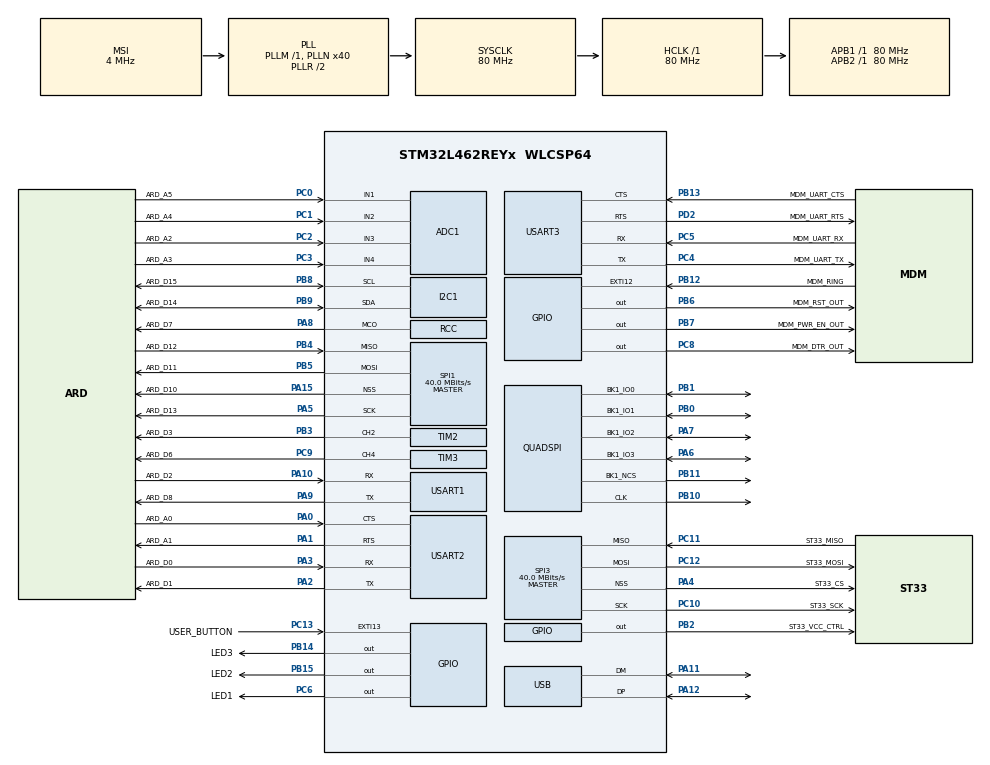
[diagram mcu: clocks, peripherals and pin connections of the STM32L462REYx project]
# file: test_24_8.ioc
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ADC1.Channel-4\#ChannelRegularConversion=ADC_CHANNEL_1
ADC1.NbrOfConversionFlag=1
ADC1.OffsetNumber-4\#ChannelRegularConversion=ADC_OFFSET_NONE
ADC1.Rank-4\#ChannelRegularConversion=1
ADC1.SamplingTime-4\#ChannelRegularConversion=ADC_SAMPLETIME_2CYCLES_5
ADC1.SingleDiff-4\#ChannelRegularConversion=ADC_DIFFERENTIAL_ENDED
ADC1.master=1
FREERTOS.Tasks01=defaultTask,0,128,StartDefaultTask,Default,NULL
FREERTOS.configUSE_NEWLIB_REENTRANT=1
Mcu.Family=STM32L4
Mcu.Name=STM32L462REYx
Mcu.Package=WLCSP64
NVIC.EXTI15_10_IRQn=true\:5\:0\:false\:false\:true\:true\:true\:true\:true
NVIC.PriorityGroup=NVIC_PRIORITYGROUP_4
NVIC.TIM1_UP_TIM16_IRQn=true\:0\:0\:false\:false\:true\:false\:false\:true\:true
NVIC.TimeBase=TIM1_UP_TIM16_IRQn
NVIC.TimeBaseIP=TIM1
NVIC.USART1_IRQn=true\:5\:0\:false\:false\:true\:true\:true\:true\:true
NVIC.USART2_IRQn=true\:5\:0\:false\:false\:true\:true\:true\:true\:true
NVIC.USART3_IRQn=true\:5\:0\:false\:false\:true\:true\:true\:true\:true
PA0.GPIO_Label=ARD_A0
PA0.Mode=CTS_RTS
PA0.Signal=USART2_CTS
PA1.GPIO_Label=ARD_A1
PA1.Mode=CTS_RTS
PA1.Signal=USART2_RTS
PA10.GPIO_Label=ARD_D2
PA10.Mode=Asynchronous
PA10.Signal=USART1_RX
PA11.Mode=Device
PA11.Signal=USB_DM
PA12.Mode=Device
PA12.Signal=USB_DP
PA13\ (JTMS/SWDIO).Mode=Serial_Wire
PA13\ (JTMS/SWDIO).Signal=SYS_JTMS-SWDIO
PA14\ (JTCK/SWCLK).Mode=Serial_Wire
PA14\ (JTCK/SWCLK).Signal=SYS_JTCK-SWCLK
PA15\ (JTDI).GPIO_Label=ARD_D10
PA15\ (JTDI).Mode=NSS_Signal_Hard_Output
PA15\ (JTDI).Signal=SPI1_NSS
PA2.GPIO_Label=ARD_D1
PA2.Mode=Asynchronous
PA2.Signal=USART2_TX
PA3.GPIO_Label=ARD_D0
PA3.Mode=Asynchronous
PA3.Signal=USART2_RX
PA4.GPIO_Label=ST33_CS
PA4.Mode=NSS_Signal_Hard_Output
PA4.Signal=SPI3_NSS
PA5.GPIO_Label=ARD_D13
PA5.Mode=Full_Duplex_Master
PA5.Signal=SPI1_SCK
PA6.Mode=Single Bank 1
PA6.Signal=QUADSPI_BK1_IO3
PA7.Mode=Single Bank 1
PA7.Signal=QUADSPI_BK1_IO2
PA8.GPIO_Label=ARD_D7
PA8.Mode=Clock-out
PA8.Signal=RCC_MCO
PA9.GPIO_Label=ARD_D8
PA9.Mode=Asynchronous
PA9.Signal=USART1_TX
PB0.Mode=Single Bank 1
PB0.Signal=QUADSPI_BK1_IO1
PB1.Mode=Single Bank 1
PB1.Signal=QUADSPI_BK1_IO0
PB10.Mode=Single Bank 1
PB10.Signal=QUADSPI_CLK
PB11.Mode=Single Bank 1
PB11.Signal=QUADSPI_BK1_NCS
PB12.GPIO_Label=MDM_RING
PB12.Signal=GPXTI12
PB13.GPIO_Label=MDM_UART_CTS
PB13.Mode=CTS_RTS
PB13.Signal=USART3_CTS
PB14.GPIO_Label=LED3
PB14.Signal=GPIO_Output
PB15.GPIO_Label=LED2
PB15.Signal=GPIO_Output
PB2.GPIO_Label=ST33_VCC_CTRL
PB2.Signal=GPIO_Output
PB3\ (JTDO/TRACESWO).GPIO_Label=ARD_D3
PB3\ (JTDO/TRACESWO).Signal=S_TIM2_CH2
PB4\ (NJTRST).GPIO_Label=ARD_D12
PB4\ (NJTRST).Mode=Full_Duplex_Master
PB4\ (NJTRST).Signal=SPI1_MISO
PB5.GPIO_Label=ARD_D11
PB5.Mode=Full_Duplex_Master
PB5.Signal=SPI1_MOSI
PB6.GPIO_Label=MDM_RST_OUT
PB6.Signal=GPIO_Output
PB7.GPIO_Label=MDM_PWR_EN_OUT
PB7.Signal=GPIO_Output
PB8.GPIO_Label=ARD_D15
PB8.GPIO_Pu=GPIO_PULLUP
PB8.Mode=I2C
PB8.Signal=I2C1_SCL
PB9.GPIO_Label=ARD_D14
PB9.GPIO_Pu=GPIO_PULLUP
PB9.Mode=I2C
PB9.Signal=I2C1_SDA
PC0.GPIO_Label=ARD_A5
PC0.Signal=ADCx_IN1
PC1.GPIO_Label=ARD_A4
PC1.Signal=ADCx_IN2
PC10.GPIO_Label=ST33_SCK
PC10.Mode=Full_Duplex_Master
PC10.Signal=SPI3_SCK
PC11.GPIO_Label=ST33_MISO
PC11.Mode=Full_Duplex_Master
PC11.Signal=SPI3_MISO
PC12.GPIO_Label=ST33_MOSI
PC12.Mode=Full_Duplex_Master
PC12.Signal=SPI3_MOSI
PC13.GPIO_Label=USER_BUTTON
PC13.GPIO_ModeDefaultEXTI=GPIO_MODE_IT_FALLING
PC13.Signal=GPXTI13
PC14-OSC32_IN\ (PC14).Mode=LSE-External-Oscillator
PC14-OSC32_IN\ (PC14).Signal=RCC_OSC32_IN
PC15-OSC32_OUT\ (PC15).Mode=LSE-External-Oscillator
PC15-OSC32_OUT\ (PC15).Signal=RCC_OSC32_OUT
PC2.GPIO_Label=ARD_A2
PC2.Signal=ADCx_IN3
PC3.GPIO_Label=ARD_A3
PC3.Signal=ADCx_IN4
PC4.GPIO_Label=MDM_UART_TX
PC4.Mode=Asynchronous
PC4.Signal=USART3_TX
PC5.GPIO_Label=MDM_UART_RX
PC5.Mode=Asynchronous
PC5.Signal=USART3_RX
PC6.GPIO_Label=LED1
PC6.Signal=GPIO_Output
PC8.GPIO_Label=MDM_DTR_OUT
PC8.Signal=GPIO_Output
PC9.GPIO_Label=ARD_D6
PC9.Signal=S_TIM3_CH4
PD2.GPIO_Label=MDM_UART_RTS
PD2.Mode=CTS_RTS
PD2.Signal=USART3_RTS
PH0-OSC_IN\ (PH0).Mode=HSE-External-Oscillator
PH0-OSC_IN\ (PH0).Signal=RCC_OSC_IN
PH1-OSC_OUT\ (PH1).Mode=HSE-External-Oscillator
PH1-OSC_OUT\ (PH1).Signal=RCC_OSC_OUT
ProjectManager.HeapSize=0x200
ProjectManager.StackSize=0x400
ProjectManager.TargetToolchain=STM32CubeIDE
RCC.ADCFreq_Value=48000000
RCC.AHBFreq_Value=80000000
RCC.APB1Freq_Value=80000000
RCC.APB1TimFreq_Value=80000000
RCC.APB2Freq_Value=80000000
RCC.APB2TimFreq_Value=80000000
RCC.CortexFreq_Value=80000000
RCC.HCLKFreq_Value=80000000
RCC.HSE_VALUE=8000000
RCC.HSI48_VALUE=48000000
RCC.HSI_VALUE=16000000
RCC.MSI_VALUE=4000000
RCC.PLLN=40
RCC.PLLSAI1N=24
RCC.RTCClockSelection=RCC_RTCCLKSOURCE_LSE
RCC.SYSCLKFreq_VALUE=80000000
RCC.SYSCLKSource=RCC_SYSCLKSOURCE_PLLCLK
RCC.USBFreq_Value=48000000
RCC.VCOOutputFreq_Value=160000000
SH.ADCx_IN1.0=ADC1_IN1,IN1-Differential
SH.ADCx_IN2.0=ADC1_IN2,IN1-Differential
SH.ADCx_IN3.0=ADC1_IN3,IN3-Differential
SH.ADCx_IN4.0=ADC1_IN4,IN3-Differential
SH.S_TIM2_CH2.0=TIM2_CH2,PWM Generation2 CH2
SH.S_TIM3_CH4.0=TIM3_CH4,PWM Generation4 CH4
SPI1.CalculateBaudRate=40.0 MBits/s
SPI1.Direction=SPI_DIRECTION_2LINES
SPI1.Mode=SPI_MODE_MASTER
SPI1.VirtualNSS=VM_NSSHARD
SPI1.VirtualType=VM_MASTER
SPI3.CalculateBaudRate=40.0 MBits/s
SPI3.Direction=SPI_DIRECTION_2LINES
SPI3.Mode=SPI_MODE_MASTER
SPI3.VirtualNSS=VM_NSSHARD
SPI3.VirtualType=VM_MASTER
TIM2.Channel-PWM\ Generation2\ CH2=TIM_CHANNEL_2
TIM3.Channel-PWM\ Generation4\ CH4=TIM_CHANNEL_4
USART1.VirtualMode-Asynchronous=VM_ASYNC
USART2.VirtualMode-Asynchronous=VM_ASYNC
USART3.VirtualMode-Asynchronous=VM_ASYNC
VP_FREERTOS_VS_CMSIS_V1.Mode=CMSIS_V1
VP_RNG_VS_RNG.Mode=RNG_Activate
VP_RTC_VS_RTC_Activate.Mode=RTC_Enabled
VP_SYS_VS_tim1.Mode=TIM1
board=B-L462E-CELL1

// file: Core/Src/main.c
/* USER CODE BEGIN Header */
/**
  ******************************************************************************
  * @file           : main.c
  * @brief          : Main program body
  ******************************************************************************
  * @attention
  *
  * Copyright (c) 2025 STMicroelectronics.
  * All rights reserved.
  *
  * This software is licensed under terms that can be found in the LICENSE file
  * in the root directory of this software component.
  * If no LICENSE file comes with this software, it is provided AS-IS.
  *
  ******************************************************************************
  */
/* USER CODE END Header */
#include "main.h"
#include "cmsis_os.h"
#include <string.h>
#include <stdio.h>
#include "lsm303agr.h"

ADC_HandleTypeDef hadc1;

I2C_HandleTypeDef hi2c1;

QSPI_HandleTypeDef hqspi;

RNG_HandleTypeDef hrng;

RTC_HandleTypeDef hrtc;

SPI_HandleTypeDef hspi1;
SPI_HandleTypeDef hspi3;

TIM_HandleTypeDef htim2;
TIM_HandleTypeDef htim3;

UART_HandleTypeDef huart1;
UART_HandleTypeDef huart2;
UART_HandleTypeDef huart3;

PCD_HandleTypeDef hpcd_USB_FS;

osThreadId defaultTaskHandle;

void SystemClock_Config(void);
void PeriphCommonClock_Config(void);
static void MX_GPIO_Init(void);
static void MX_ADC1_Init(void);
static void MX_I2C1_Init(void);
static void MX_QUADSPI_Init(void);
static void MX_RNG_Init(void);
static void MX_RTC_Init(void);
static void MX_SPI1_Init(void);
static void MX_SPI3_Init(void);
static void MX_TIM2_Init(void);
static void MX_TIM3_Init(void);
static void MX_USART1_UART_Init(void);
static void MX_USART2_UART_Init(void);
static void MX_USART3_UART_Init(void);
static void MX_USB_PCD_Init(void);
void StartDefaultTask(void const * argument);

static int16_t accel_data[3];
static char uart_tx_buffer[100];
static char msg[] = "Hello World!\r\n";

int main(void)
{

  /* MCU Configuration--------------------------------------------------------*/

  /* Reset of all peripherals, Initializes the Flash interface and the Systick. */
  HAL_Init();

  /* Configure the system clock */
  SystemClock_Config();

  /* Configure the peripherals common clocks */
  PeriphCommonClock_Config();

  /* Initialize all configured peripherals */
  MX_GPIO_Init();
  MX_ADC1_Init();
  MX_I2C1_Init();
  MX_QUADSPI_Init();
  MX_RNG_Init();
  MX_RTC_Init();
  MX_SPI1_Init();
  MX_SPI3_Init();
  MX_TIM2_Init();
  MX_TIM3_Init();
  MX_USART1_UART_Init();
  MX_USART2_UART_Init();
  MX_USART3_UART_Init();
  MX_USB_PCD_Init();
  /* USER CODE BEGIN 2 */
  uint16_t accel_config = LSM303AGR_ODR_100_HZ | LSM303AGR_AXES_ENABLE;
  LSM303AGR_AccInit(accel_config);
  /* USER CODE END 2 */

  /* Create the thread(s) */
  /* definition and creation of defaultTask */
  osThreadDef(defaultTask, StartDefaultTask, osPriorityNormal, 0, 128);
  defaultTaskHandle = osThreadCreate(osThread(defaultTask), NULL);

  /* Start scheduler */
  osKernelStart();

  /* We should never get here as control is now taken by the scheduler */

  /* Infinite loop */
  while (1)
  {

  }
}

void SystemClock_Config(void)
{
  RCC_OscInitTypeDef RCC_OscInitStruct = {0};
  RCC_ClkInitTypeDef RCC_ClkInitStruct = {0};

  /** Configure the main internal regulator output voltage
  */
  if (HAL_PWREx_ControlVoltageScaling(PWR_REGULATOR_VOLTAGE_SCALE1) != HAL_OK)
  {
    Error_Handler();
  }

  /** Configure LSE Drive Capability
  */
  HAL_PWR_EnableBkUpAccess();
  __HAL_RCC_LSEDRIVE_CONFIG(RCC_LSEDRIVE_LOW);

  /** Initializes the RCC Oscillators according to the specified parameters
  * in the RCC_OscInitTypeDef structure.
  */
  RCC_OscInitStruct.OscillatorType = RCC_OSCILLATORTYPE_LSE|RCC_OSCILLATORTYPE_MSI;
  RCC_OscInitStruct.LSEState = RCC_LSE_ON;
  RCC_OscInitStruct.MSIState = RCC_MSI_ON;
  RCC_OscInitStruct.MSICalibrationValue = 0;
  RCC_OscInitStruct.MSIClockRange = RCC_MSIRANGE_6;
  RCC_OscInitStruct.PLL.PLLState = RCC_PLL_ON;
  RCC_OscInitStruct.PLL.PLLSource = RCC_PLLSOURCE_MSI;
  RCC_OscInitStruct.PLL.PLLM = 1;
  RCC_OscInitStruct.PLL.PLLN = 40;
  RCC_OscInitStruct.PLL.PLLP = RCC_PLLP_DIV7;
  RCC_OscInitStruct.PLL.PLLQ = RCC_PLLQ_DIV2;
  RCC_OscInitStruct.PLL.PLLR = RCC_PLLR_DIV2;
  if (HAL_RCC_OscConfig(&RCC_OscInitStruct) != HAL_OK)
  {
    Error_Handler();
  }

  /** Initializes the CPU, AHB and APB buses clocks
  */
  RCC_ClkInitStruct.ClockType = RCC_CLOCKTYPE_HCLK|RCC_CLOCKTYPE_SYSCLK
                              |RCC_CLOCKTYPE_PCLK1|RCC_CLOCKTYPE_PCLK2;
  RCC_ClkInitStruct.SYSCLKSource = RCC_SYSCLKSOURCE_PLLCLK;
  RCC_ClkInitStruct.AHBCLKDivider = RCC_SYSCLK_DIV1;
  RCC_ClkInitStruct.APB1CLKDivider = RCC_HCLK_DIV1;
  RCC_ClkInitStruct.APB2CLKDivider = RCC_HCLK_DIV1;

  if (HAL_RCC_ClockConfig(&RCC_ClkInitStruct, FLASH_LATENCY_4) != HAL_OK)
  {
    Error_Handler();
  }
  HAL_RCC_MCOConfig(RCC_MCO1, RCC_MCO1SOURCE_SYSCLK, RCC_MCODIV_1);

  /** Enable MSI Auto calibration
  */
  HAL_RCCEx_EnableMSIPLLMode();
}

void PeriphCommonClock_Config(void)
{
  RCC_PeriphCLKInitTypeDef PeriphClkInit = {0};

  /** Initializes the peripherals clock
  */
  PeriphClkInit.PeriphClockSelection = RCC_PERIPHCLK_USB|RCC_PERIPHCLK_RNG
                              |RCC_PERIPHCLK_ADC;
  PeriphClkInit.AdcClockSelection = RCC_ADCCLKSOURCE_PLLSAI1;
  PeriphClkInit.UsbClockSelection = RCC_USBCLKSOURCE_PLLSAI1;
  PeriphClkInit.RngClockSelection = RCC_RNGCLKSOURCE_PLLSAI1;
  PeriphClkInit.PLLSAI1.PLLSAI1Source = RCC_PLLSOURCE_MSI;
  PeriphClkInit.PLLSAI1.PLLSAI1M = 1;
  PeriphClkInit.PLLSAI1.PLLSAI1N = 24;
  PeriphClkInit.PLLSAI1.PLLSAI1P = RCC_PLLP_DIV7;
  PeriphClkInit.PLLSAI1.PLLSAI1Q = RCC_PLLQ_DIV2;
  PeriphClkInit.PLLSAI1.PLLSAI1R = RCC_PLLR_DIV2;
  PeriphClkInit.PLLSAI1.PLLSAI1ClockOut = RCC_PLLSAI1_48M2CLK|RCC_PLLSAI1_ADC1CLK;
  if (HAL_RCCEx_PeriphCLKConfig(&PeriphClkInit) != HAL_OK)
  {
    Error_Handler();
  }
}

static void MX_ADC1_Init(void)
{

  ADC_ChannelConfTypeDef sConfig = {0};

  /** Common config
  */
  hadc1.Instance = ADC1;
  hadc1.Init.ClockPrescaler = ADC_CLOCK_ASYNC_DIV1;
  hadc1.Init.Resolution = ADC_RESOLUTION_12B;
  hadc1.Init.DataAlign = ADC_DATAALIGN_RIGHT;
  hadc1.Init.ScanConvMode = ADC_SCAN_DISABLE;
  hadc1.Init.EOCSelection = ADC_EOC_SINGLE_CONV;
  hadc1.Init.LowPowerAutoWait = DISABLE;
  hadc1.Init.ContinuousConvMode = DISABLE;
  hadc1.Init.NbrOfConversion = 1;
  hadc1.Init.DiscontinuousConvMode = DISABLE;
  hadc1.Init.ExternalTrigConv = ADC_SOFTWARE_START;
  hadc1.Init.ExternalTrigConvEdge = ADC_EXTERNALTRIGCONVEDGE_NONE;
  hadc1.Init.DMAContinuousRequests = DISABLE;
  hadc1.Init.Overrun = ADC_OVR_DATA_PRESERVED;
  hadc1.Init.OversamplingMode = DISABLE;
  if (HAL_ADC_Init(&hadc1) != HAL_OK)
  {
    Error_Handler();
  }

  /** Configure Regular Channel
  */
  sConfig.Channel = ADC_CHANNEL_1;
  sConfig.Rank = ADC_REGULAR_RANK_1;
  sConfig.SamplingTime = ADC_SAMPLETIME_2CYCLES_5;
  sConfig.SingleDiff = ADC_DIFFERENTIAL_ENDED;
  sConfig.OffsetNumber = ADC_OFFSET_NONE;
  sConfig.Offset = 0;
  if (HAL_ADC_ConfigChannel(&hadc1, &sConfig) != HAL_OK)
  {
    Error_Handler();
  }

}

static void MX_I2C1_Init(void)
{

  hi2c1.Instance = I2C1;
  hi2c1.Init.Timing = 0x00000E14;
  hi2c1.Init.OwnAddress1 = 0;
  hi2c1.Init.AddressingMode = I2C_ADDRESSINGMODE_7BIT;
  hi2c1.Init.DualAddressMode = I2C_DUALADDRESS_DISABLE;
  hi2c1.Init.OwnAddress2 = 0;
  hi2c1.Init.OwnAddress2Masks = I2C_OA2_NOMASK;
  hi2c1.Init.GeneralCallMode = I2C_GENERALCALL_DISABLE;
  hi2c1.Init.NoStretchMode = I2C_NOSTRETCH_DISABLE;
  if (HAL_I2C_Init(&hi2c1) != HAL_OK)
  {
    Error_Handler();
  }

  /** Configure Analogue filter
  */
  if (HAL_I2CEx_ConfigAnalogFilter(&hi2c1, I2C_ANALOGFILTER_ENABLE) != HAL_OK)
  {
    Error_Handler();
  }

  /** Configure Digital filter
  */
  if (HAL_I2CEx_ConfigDigitalFilter(&hi2c1, 0) != HAL_OK)
  {
    Error_Handler();
  }

}

static void MX_QUADSPI_Init(void)
{

  /* QUADSPI parameter configuration*/
  hqspi.Instance = QUADSPI;
  hqspi.Init.ClockPrescaler = 255;
  hqspi.Init.FifoThreshold = 1;
  hqspi.Init.SampleShifting = QSPI_SAMPLE_SHIFTING_NONE;
  hqspi.Init.FlashSize = 1;
  hqspi.Init.ChipSelectHighTime = QSPI_CS_HIGH_TIME_1_CYCLE;
  hqspi.Init.ClockMode = QSPI_CLOCK_MODE_0;
  hqspi.Init.FlashID = QSPI_FLASH_ID_1;
  hqspi.Init.DualFlash = QSPI_DUALFLASH_DISABLE;
  if (HAL_QSPI_Init(&hqspi) != HAL_OK)
  {
    Error_Handler();
  }

}

static void MX_RNG_Init(void)
{

  hrng.Instance = RNG;
  if (HAL_RNG_Init(&hrng) != HAL_OK)
  {
    Error_Handler();
  }

}

static void MX_RTC_Init(void)
{

  /** Initialize RTC Only
  */
  hrtc.Instance = RTC;
  hrtc.Init.HourFormat = RTC_HOURFORMAT_24;
  hrtc.Init.AsynchPrediv = 127;
  hrtc.Init.SynchPrediv = 255;
  hrtc.Init.OutPut = RTC_OUTPUT_DISABLE;
  hrtc.Init.OutPutRemap = RTC_OUTPUT_REMAP_NONE;
  hrtc.Init.OutPutPolarity = RTC_OUTPUT_POLARITY_HIGH;
  hrtc.Init.OutPutType = RTC_OUTPUT_TYPE_OPENDRAIN;
  if (HAL_RTC_Init(&hrtc) != HAL_OK)
  {
    Error_Handler();
  }

}

static void MX_SPI1_Init(void)
{

  /* SPI1 parameter configuration*/
  hspi1.Instance = SPI1;
  hspi1.Init.Mode = SPI_MODE_MASTER;
  hspi1.Init.Direction = SPI_DIRECTION_2LINES;
  hspi1.Init.DataSize = SPI_DATASIZE_4BIT;
  hspi1.Init.CLKPolarity = SPI_POLARITY_LOW;
  hspi1.Init.CLKPhase = SPI_PHASE_1EDGE;
  hspi1.Init.NSS = SPI_NSS_HARD_OUTPUT;
  hspi1.Init.BaudRatePrescaler = SPI_BAUDRATEPRESCALER_2;
  hspi1.Init.FirstBit = SPI_FIRSTBIT_MSB;
  hspi1.Init.TIMode = SPI_TIMODE_DISABLE;
  hspi1.Init.CRCCalculation = SPI_CRCCALCULATION_DISABLE;
  hspi1.Init.CRCPolynomial = 7;
  hspi1.Init.CRCLength = SPI_CRC_LENGTH_DATASIZE;
  hspi1.Init.NSSPMode = SPI_NSS_PULSE_ENABLE;
  if (HAL_SPI_Init(&hspi1) != HAL_OK)
  {
    Error_Handler();
  }

}

static void MX_SPI3_Init(void)
{

  /* SPI3 parameter configuration*/
  hspi3.Instance = SPI3;
  hspi3.Init.Mode = SPI_MODE_MASTER;
  hspi3.Init.Direction = SPI_DIRECTION_2LINES;
  hspi3.Init.DataSize = SPI_DATASIZE_4BIT;
  hspi3.Init.CLKPolarity = SPI_POLARITY_LOW;
  hspi3.Init.CLKPhase = SPI_PHASE_1EDGE;
  hspi3.Init.NSS = SPI_NSS_HARD_OUTPUT;
  hspi3.Init.BaudRatePrescaler = SPI_BAUDRATEPRESCALER_2;
  hspi3.Init.FirstBit = SPI_FIRSTBIT_MSB;
  hspi3.Init.TIMode = SPI_TIMODE_DISABLE;
  hspi3.Init.CRCCalculation = SPI_CRCCALCULATION_DISABLE;
  hspi3.Init.CRCPolynomial = 7;
  hspi3.Init.CRCLength = SPI_CRC_LENGTH_DATASIZE;
  hspi3.Init.NSSPMode = SPI_NSS_PULSE_ENABLE;
  if (HAL_SPI_Init(&hspi3) != HAL_OK)
  {
    Error_Handler();
  }

}

static void MX_TIM2_Init(void)
{

  TIM_MasterConfigTypeDef sMasterConfig = {0};
  TIM_OC_InitTypeDef sConfigOC = {0};

  htim2.Instance = TIM2;
  htim2.Init.Prescaler = 0;
  htim2.Init.CounterMode = TIM_COUNTERMODE_UP;
  htim2.Init.Period = 4294967295;
  htim2.Init.ClockDivision = TIM_CLOCKDIVISION_DIV1;
  htim2.Init.AutoReloadPreload = TIM_AUTORELOAD_PRELOAD_DISABLE;
  if (HAL_TIM_PWM_Init(&htim2) != HAL_OK)
  {
    Error_Handler();
  }
  sMasterConfig.MasterOutputTrigger = TIM_TRGO_RESET;
  sMasterConfig.MasterSlaveMode = TIM_MASTERSLAVEMODE_DISABLE;
  if (HAL_TIMEx_MasterConfigSynchronization(&htim2, &sMasterConfig) != HAL_OK)
  {
    Error_Handler();
  }
  sConfigOC.OCMode = TIM_OCMODE_PWM1;
  sConfigOC.Pulse = 0;
  sConfigOC.OCPolarity = TIM_OCPOLARITY_HIGH;
  sConfigOC.OCFastMode = TIM_OCFAST_DISABLE;
  if (HAL_TIM_PWM_ConfigChannel(&htim2, &sConfigOC, TIM_CHANNEL_2) != HAL_OK)
  {
    Error_Handler();
  }
  HAL_TIM_MspPostInit(&htim2);

}

static void MX_TIM3_Init(void)
{

  TIM_MasterConfigTypeDef sMasterConfig = {0};
  TIM_OC_InitTypeDef sConfigOC = {0};

  htim3.Instance = TIM3;
  htim3.Init.Prescaler = 0;
  htim3.Init.CounterMode = TIM_COUNTERMODE_UP;
  htim3.Init.Period = 65535;
  htim3.Init.ClockDivision = TIM_CLOCKDIVISION_DIV1;
  htim3.Init.AutoReloadPreload = TIM_AUTORELOAD_PRELOAD_DISABLE;
  if (HAL_TIM_PWM_Init(&htim3) != HAL_OK)
  {
    Error_Handler();
  }
  sMasterConfig.MasterOutputTrigger = TIM_TRGO_RESET;
  sMasterConfig.MasterSlaveMode = TIM_MASTERSLAVEMODE_DISABLE;
  if (HAL_TIMEx_MasterConfigSynchronization(&htim3, &sMasterConfig) != HAL_OK)
  {
    Error_Handler();
  }
  sConfigOC.OCMode = TIM_OCMODE_PWM1;
  sConfigOC.Pulse = 0;
  sConfigOC.OCPolarity = TIM_OCPOLARITY_HIGH;
  sConfigOC.OCFastMode = TIM_OCFAST_DISABLE;
  if (HAL_TIM_PWM_ConfigChannel(&htim3, &sConfigOC, TIM_CHANNEL_4) != HAL_OK)
  {
    Error_Handler();
  }
  HAL_TIM_MspPostInit(&htim3);

}

static void MX_USART1_UART_Init(void)
{

  huart1.Instance = USART1;
  huart1.Init.BaudRate = 115200;
  huart1.Init.WordLength = UART_WORDLENGTH_8B;
  huart1.Init.StopBits = UART_STOPBITS_1;
  huart1.Init.Parity = UART_PARITY_NONE;
  huart1.Init.Mode = UART_MODE_TX_RX;
  huart1.Init.HwFlowCtl = UART_HWCONTROL_NONE;
  huart1.Init.OverSampling = UART_OVERSAMPLING_16;
  huart1.Init.OneBitSampling = UART_ONE_BIT_SAMPLE_DISABLE;
  huart1.AdvancedInit.AdvFeatureInit = UART_ADVFEATURE_NO_INIT;
  if (HAL_UART_Init(&huart1) != HAL_OK)
  {
    Error_Handler();
  }

}

static void MX_USART2_UART_Init(void)
{

  huart2.Instance = USART2;
  huart2.Init.BaudRate = 115200;
  huart2.Init.WordLength = UART_WORDLENGTH_8B;
  huart2.Init.StopBits = UART_STOPBITS_1;
  huart2.Init.Parity = UART_PARITY_NONE;
  huart2.Init.Mode = UART_MODE_TX_RX;
  huart2.Init.HwFlowCtl = UART_HWCONTROL_RTS_CTS;
  huart2.Init.OverSampling = UART_OVERSAMPLING_16;
  huart2.Init.OneBitSampling = UART_ONE_BIT_SAMPLE_DISABLE;
  huart2.AdvancedInit.AdvFeatureInit = UART_ADVFEATURE_NO_INIT;
  if (HAL_UART_Init(&huart2) != HAL_OK)
  {
    Error_Handler();
  }

}

static void MX_USART3_UART_Init(void)
{

  huart3.Instance = USART3;
  huart3.Init.BaudRate = 115200;
  huart3.Init.WordLength = UART_WORDLENGTH_8B;
  huart3.Init.StopBits = UART_STOPBITS_1;
  huart3.Init.Parity = UART_PARITY_NONE;
  huart3.Init.Mode = UART_MODE_TX_RX;
  huart3.Init.HwFlowCtl = UART_HWCONTROL_RTS_CTS;
  huart3.Init.OverSampling = UART_OVERSAMPLING_16;
  huart3.Init.OneBitSampling = UART_ONE_BIT_SAMPLE_DISABLE;
  huart3.AdvancedInit.AdvFeatureInit = UART_ADVFEATURE_NO_INIT;
  if (HAL_UART_Init(&huart3) != HAL_OK)
  {
    Error_Handler();
  }

}

static void MX_USB_PCD_Init(void)
{

  hpcd_USB_FS.Instance = USB;
  hpcd_USB_FS.Init.dev_endpoints = 8;
  hpcd_USB_FS.Init.speed = PCD_SPEED_FULL;
  hpcd_USB_FS.Init.phy_itface = PCD_PHY_EMBEDDED;
  hpcd_USB_FS.Init.Sof_enable = DISABLE;
  hpcd_USB_FS.Init.low_power_enable = DISABLE;
  hpcd_USB_FS.Init.lpm_enable = DISABLE;
  hpcd_USB_FS.Init.battery_charging_enable = DISABLE;
  if (HAL_PCD_Init(&hpcd_USB_FS) != HAL_OK)
  {
    Error_Handler();
  }

}

static void MX_GPIO_Init(void)
{
  GPIO_InitTypeDef GPIO_InitStruct = {0};

  /* GPIO Ports Clock Enable */
  __HAL_RCC_GPIOA_CLK_ENABLE();
  __HAL_RCC_GPIOC_CLK_ENABLE();
  __HAL_RCC_GPIOB_CLK_ENABLE();
  __HAL_RCC_GPIOD_CLK_ENABLE();
  __HAL_RCC_GPIOH_CLK_ENABLE();

  /*Configure GPIO pin Output Level */
  HAL_GPIO_WritePin(GPIOB, MDM_PWR_EN_OUT_Pin|MDM_RST_OUT_Pin|LED2_Pin|LED3_Pin
                          |ST33_VCC_CTRL_Pin, GPIO_PIN_RESET);

  /*Configure GPIO pin Output Level */
  HAL_GPIO_WritePin(GPIOC, LED1_Pin|MDM_DTR_OUT_Pin, GPIO_PIN_RESET);

  /*Configure GPIO pins : MDM_PWR_EN_OUT_Pin MDM_RST_OUT_Pin LED2_Pin LED3_Pin
                           ST33_VCC_CTRL_Pin */
  GPIO_InitStruct.Pin = MDM_PWR_EN_OUT_Pin|MDM_RST_OUT_Pin|LED2_Pin|LED3_Pin
                          |ST33_VCC_CTRL_Pin;
  GPIO_InitStruct.Mode = GPIO_MODE_OUTPUT_PP;
  GPIO_InitStruct.Pull = GPIO_NOPULL;
  GPIO_InitStruct.Speed = GPIO_SPEED_FREQ_LOW;
  HAL_GPIO_Init(GPIOB, &GPIO_InitStruct);

  /*Configure GPIO pin : USER_BUTTON_Pin */
  GPIO_InitStruct.Pin = USER_BUTTON_Pin;
  GPIO_InitStruct.Mode = GPIO_MODE_IT_FALLING;
  GPIO_InitStruct.Pull = GPIO_NOPULL;
  HAL_GPIO_Init(USER_BUTTON_GPIO_Port, &GPIO_InitStruct);

  /*Configure GPIO pin : ARD_D7_Pin */
  GPIO_InitStruct.Pin = ARD_D7_Pin;
  GPIO_InitStruct.Mode = GPIO_MODE_AF_PP;
  GPIO_InitStruct.Pull = GPIO_NOPULL;
  GPIO_InitStruct.Speed = GPIO_SPEED_FREQ_LOW;
  GPIO_InitStruct.Alternate = GPIO_AF0_MCO;
  HAL_GPIO_Init(ARD_D7_GPIO_Port, &GPIO_InitStruct);

  /*Configure GPIO pins : LED1_Pin MDM_DTR_OUT_Pin */
  GPIO_InitStruct.Pin = LED1_Pin|MDM_DTR_OUT_Pin;
  GPIO_InitStruct.Mode = GPIO_MODE_OUTPUT_PP;
  GPIO_InitStruct.Pull = GPIO_NOPULL;
  GPIO_InitStruct.Speed = GPIO_SPEED_FREQ_LOW;
  HAL_GPIO_Init(GPIOC, &GPIO_InitStruct);

  /*Configure GPIO pin : MDM_RING_Pin */
  GPIO_InitStruct.Pin = MDM_RING_Pin;
  GPIO_InitStruct.Mode = GPIO_MODE_IT_RISING;
  GPIO_InitStruct.Pull = GPIO_NOPULL;
  HAL_GPIO_Init(MDM_RING_GPIO_Port, &GPIO_InitStruct);

  /* EXTI interrupt init*/
  HAL_NVIC_SetPriority(EXTI15_10_IRQn, 5, 0);
  HAL_NVIC_EnableIRQ(EXTI15_10_IRQn);

}

void StartDefaultTask(void const * argument)
{
  /* USER CODE BEGIN 5 */
  /* Infinite loop */
//  int16_t accel_data[3] = {1, 2, 3};
  uint32_t time_out = 500;
//  char uart_tx_buffer[100] = "Hi\n";
//  char msg[] = "Hello World!\n";
  HAL_UART_Transmit(&huart1, (const uint8_t*) msg, strlen(msg), time_out);
  for(;;)
  {
	LSM303AGR_AccReadXYZ(accel_data);
	// Format the accelerometer data into a string
	// The values are in milligravity (mg).
	sprintf(uart_tx_buffer, "Accel (mg) - X:%d, Y:%d, Z:%d\r\n", accel_data[0], accel_data[1], accel_data[2]);

	// Transmit the string via UART
	HAL_UART_Transmit(&huart1, (const uint8_t*)uart_tx_buffer, strlen(uart_tx_buffer), time_out);
	HAL_UART_Transmit(&huart1, (const uint8_t*) msg, strlen(msg), time_out);
    osDelay(1000);
  }
  /* USER CODE END 5 */
}

void HAL_TIM_PeriodElapsedCallback(TIM_HandleTypeDef *htim)
{
  if (htim->Instance == TIM1)
  {
    HAL_IncTick();
  }
}

void Error_Handler(void)
{
  __disable_irq();
  while (1)
  {
  }
}
